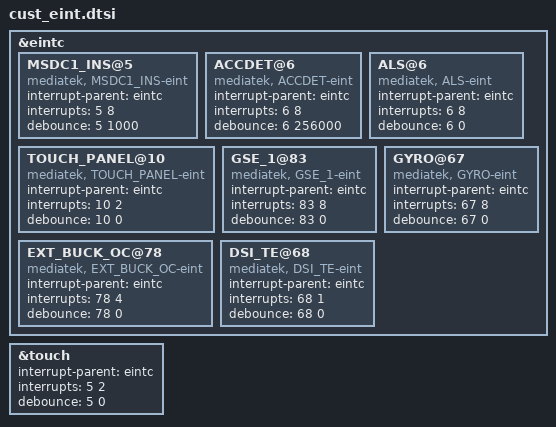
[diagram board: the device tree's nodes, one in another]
/*
 * Generated by MTK SP Drv_CodeGen Version 03.13.6  for MT6735. Copyright MediaTek Inc. (C) 2013.
 * Thu May 28 10:14:14 2015
 * Do Not Modify the File.
 */

/*************************
 * EINT DTSI File
*************************/

#include <dt-bindings/interrupt-controller/irq.h>
#include <dt-bindings/interrupt-controller/arm-gic.h>

&eintc {
	MSDC1_INS@5 {
		compatible = "mediatek, MSDC1_INS-eint";
		interrupt-parent = <&eintc>;
		interrupts = <5 8>;
		debounce = <5 1000>;
	};

	ACCDET@6 {
		compatible = "mediatek, ACCDET-eint";
		interrupt-parent = <&eintc>;
		interrupts = <6 8>;
		debounce = <6 256000>;
	};

	TOUCH_PANEL@10 {
		compatible = "mediatek, TOUCH_PANEL-eint";
		interrupt-parent = <&eintc>;
		interrupts = <10 2>;
		debounce = <10 0>;
	};

	ALS@6 {
		compatible = "mediatek, ALS-eint";
		interrupt-parent = <&eintc>;
		interrupts = <6 8>;
		debounce = <6 0>;
	};

	GSE_1@83 {
		compatible = "mediatek, GSE_1-eint";
		interrupt-parent = <&eintc>;
		interrupts = <83 8>;
		debounce = <83 0>;
	};

	GYRO@67 {
		compatible = "mediatek, GYRO-eint";
		interrupt-parent = <&eintc>;
		interrupts = <67 8>;
		debounce = <67 0>;
	};

	EXT_BUCK_OC@78 {
		compatible = "mediatek, EXT_BUCK_OC-eint";
		interrupt-parent = <&eintc>;
		interrupts = <78 4>;
		debounce = <78 0>;
	};

	DSI_TE@68 {
		compatible = "mediatek, DSI_TE-eint";
		interrupt-parent = <&eintc>;
		interrupts = <68 1>;
		debounce = <68 0>;
	};

};
&touch {
	interrupt-parent = <&eintc>;
	interrupts = <5 2>;
	debounce = <5 0>;
};
